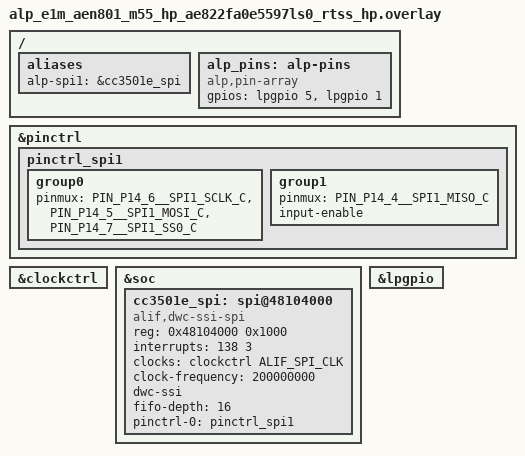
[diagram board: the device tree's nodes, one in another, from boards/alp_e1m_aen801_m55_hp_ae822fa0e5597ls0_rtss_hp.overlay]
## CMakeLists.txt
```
# SPDX-License-Identifier: Apache-2.0
cmake_minimum_required(VERSION 3.20.0)

# Auto-apply the RK055HDMIPI4MA0 DSI shield on the AEN M55-HP board targets
# this app's board.yaml actually names (`alp_e1m_aen801_m55_hp/...` and
# `alp_e1m_aen803_m55_hp/...`) -- this app's only core (board.yaml
# `cores: m55_hp:`).  The shield wires up the full Ensemble E8
# C2-MIPI-DSI DISPLAY chain (cdc200 -> mipi_dsi -> the shared D-PHY -> the
# RK055HDMIPI4MA0/HX8394 panel) on the EVK's J6 connector -- see
# examples/aen/aen-dsi-display/CMakeLists.txt for the same shield applied
# the same way (#2173).  Skipped when the caller already set SHIELD (e.g.
# `west build -DSHIELD=...`), so a user can swap in a different panel, and
# inert on every other target, including native_sim.
#
# BOARD reaches this file differently depending on the caller:
#  - a plain (non-sysbuild) `west build -b <board>` / twister's `-p
#    <platform>` both pass it in as a `-DBOARD=...` cache entry on the
#    command line, which CMake sees before this file runs, so it is
#    already a normal CMake variable below.
#  - a caller that exports BOARD instead of passing -D is covered by the
#    $ENV{BOARD} fallback.
#  - under `--sysbuild`, which is the AEN flow's documented default (see
#    docs/_aen-runbook-section.md and scripts/bench/aen/README.md),
#    sysbuild's `share/sysbuild/cmake/modules/sysbuild_extensions.cmake`
#    does NOT forward BOARD as a `-D` cache entry to the image build at
#    all (its shared_cmake_variables_list omits it); Zephyr's own
#    cmake/modules/boards.cmake resolves BOARD from the sysbuild cache
#    target instead, via zephyr_get(), *inside* find_package(Zephyr) --
#    too late to affect the regex below, which must run before
#    find_package() for SHIELD to take effect. So for sysbuild, read
#    BOARD out of the sysbuild cache file ourselves: SYSBUILD_CACHE is
#    passed to every image sub-build as a plain `-D` cache entry
#    (sysbuild_extensions.cmake's ExternalProject_Add CMAKE_ARGS), and
#    the file it points at always carries a `BOARD:STRING=<board>/<board
#    qualifiers>` line (sysbuild_extensions.cmake's sysbuild_cache()).
if(NOT DEFINED BOARD AND DEFINED ENV{BOARD})
    set(BOARD $ENV{BOARD})
endif()
if(NOT DEFINED BOARD AND DEFINED SYSBUILD_CACHE AND EXISTS "${SYSBUILD_CACHE}")
    file(STRINGS "${SYSBUILD_CACHE}" _alp_sysbuild_board_line REGEX "^BOARD:STRING=")
    if(_alp_sysbuild_board_line)
        string(REGEX REPLACE "^BOARD:STRING=" "" BOARD "${_alp_sysbuild_board_line}")
    endif()
endif()
if(DEFINED BOARD AND BOARD MATCHES "^alp_e1m_aen80[13]_m55_hp(/|$)" AND NOT DEFINED SHIELD)
    list(APPEND SHIELD e1m_evk_rk055hdmipi4ma0)
endif()

find_package(Zephyr REQUIRED HINTS $ENV{ZEPHYR_BASE})
project(iot_dashboard LANGUAGES C)

target_sources(app PRIVATE
    src/main.c
    src/dashboard_ui.c
    # Reusable SoM bring-up helper (cc3501e_bridge_bringup): the one-call
    # CC3501E bridge init this app uses so alp_wifi_open() can bind to a
    # ready bridge on E1M-AEN801 (#2112). Copyable template, same file as
    # examples/aen/aen-cc3501e-* -- see src/cc3501e_bridge.h.
    src/cc3501e_bridge.c
)
```

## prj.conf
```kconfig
# SPDX-License-Identifier: Apache-2.0
CONFIG_MAIN_STACK_SIZE=16384
CONFIG_HEAP_MEM_POOL_SIZE=262144

CONFIG_LV_Z_VDB_SIZE=50
CONFIG_LV_COLOR_DEPTH_16=y
CONFIG_LV_DEF_REFR_PERIOD=33
# LVGL doesn't ship the larger Montserrat sizes by default; the
# dashboard's big-number tiles use the 28-pt face.
CONFIG_LV_FONT_MONTSERRAT_28=y
# LVGL's own internal allocator pool -- see
# examples/display/lvgl-widgets-demo/prj.conf for why the 2048-byte
# Kconfig default is unsafe.
CONFIG_LV_Z_MEM_POOL_SIZE=131072

CONFIG_LOG=y
CONFIG_LOG_PRINTK=y

# Networking + MQTT + TLS knobs.  Real WiFi credentials come in
# via a build-time KConfig override or a CMake -D flag; the demo
# stubs out the connect step on native_sim.
CONFIG_NETWORKING=y
CONFIG_NET_IPV4=y
CONFIG_NET_TCP=y
CONFIG_NET_SOCKETS=y
CONFIG_MQTT_LIB=y
# MQTT over TLS.  This used to be forced off around the mbedtls
# ssl_misc.h break; that is fixed at its root (#2173), so the demo
# builds its real transport everywhere.
CONFIG_MQTT_LIB_TLS=y
CONFIG_DNS_RESOLVER=y

# Display subsystem.  The actual panel driver is board-specific: on AEN
# real silicon the e1m_evk_rk055hdmipi4ma0 shield (applied in
# CMakeLists.txt, #2173) brings up the RK055HDMIPI4MA0/HX8394 DSI panel
# and its `zephyr,display` chosen node, while native_sim has no panel and
# pulls CONFIG_DUMMY_DISPLAY=y from the per-example native_sim.conf
# overlay (wired in testcase.yaml).
CONFIG_DISPLAY=y

# This app binds LVGL to the panel itself via <alp/gui.h>'s
# alp_gui_lvgl_attach() (src/main.c) -- see
# examples/display/lvgl-widgets-demo/prj.conf for the full rationale
# on turning Zephyr's own lvgl auto-init off.
CONFIG_LV_Z_AUTO_INIT=n
```

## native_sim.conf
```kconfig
# SPDX-License-Identifier: Apache-2.0
#
# Native-sim Kconfig overlay for iot-dashboard.
#
# Loaded LAST via twister's `extra_args: EXTRA_CONF_FILE=...`
# (see ../testcase.yaml), so the settings here win over the
# alp.conf-emitted CONFIG_MBEDTLS=y that `libraries: [mbedtls]`
# pulls into every iot-dashboard build.
#
# The mbedtls-off block that used to live here is gone: it worked
# around the ssl_misc.h break, which is fixed at its root (#2173),
# so this target now builds the same TLS-enabled configuration the
# SoM does.  What remains is the panel wiring, which is genuinely
# native_sim-only.

# native_sim has no real DSI panel, so bind Zephyr's dummy display
# driver: it lets the dashboard link without an SDL/X11 dependency.
# On real silicon this file is NOT applied -- the RK055HDMIPI4MA0/HX8394
# panel is brought up by the e1m_evk_rk055hdmipi4ma0 shield instead
# (CMakeLists.txt, #2173) -- so the dummy-panel knob never reaches the
# real-silicon build.
CONFIG_DUMMY_DISPLAY=y

# native_sim's DTS also carries a zephyr,sdl-dc node, so CONFIG_DISPLAY=y
# (prj.conf) drags in the SDL display driver by default alongside the
# dummy one above -- see examples/display/lvgl-widgets-demo/native_sim.conf
# for why that segfaults headless. This app never opens that device,
# so keep SDL out of the build entirely.
CONFIG_SDL_DISPLAY=n

# native_sim's only entropy driver is FAKE_ENTROPY_NATIVE_SIM, whose own
# Kconfig help says it "does not generate real entropy". mbedTLS' PSA crypto
# core is on here (ALP_SDK_MBEDTLS_PSA_CRYPTO, #2173), so the weak-RNG
# refusal in zephyr/CMakeLists.txt applies and a simulator run has to
# acknowledge it (#2192). This file is native_sim-only and is NOT applied to
# a real-silicon build, so a scaffolded copy built for a SoM does not carry
# this opt-in: on AEN the SE TRNG is the default entropy source (#2192).
CONFIG_ALP_SDK_ALLOW_TEST_ENTROPY=y
```

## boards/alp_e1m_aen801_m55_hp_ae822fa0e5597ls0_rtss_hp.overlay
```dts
/*
 * Copyright (c) 2026 Alp Lab AB
 * SPDX-License-Identifier: Apache-2.0
 *
 * E1M-AEN801 M55-HP overlay for iot-dashboard.  Review on #2242 (#2173)
 * found this example shipped no AEN board overlay at all: on the AEN
 * targets the SPI1/CC3501E-bridge pads have no DT node or pinmux, so
 * cc3501e_bridge_bringup() (src/cc3501e_bridge.c, bus_id
 * CC3501E_BRIDGE_SPI_BUS_ID = 1, alp_pins WIFI_EN/NRST) could not reach
 * the CC3501E on either AEN target -- the DSI shield alone is not enough.
 *
 * This is the CC3501E bridge subset of
 * examples/peripheral-io/alp-console's bench-validated overlay -- the
 * SoM-internal Alif<->CC3501E SPI1 link + the two host-driven control
 * nets, from metadata/e1m_modules/aen/inter-chip.tsv:
 *   SPI1.SCK P14_6  MOSI P14_5  MISO P14_4   WIFI_EN P15_5  NRST P15_1_FLEX
 * iot-dashboard has no I2C sensor-manifest bus of its own here (BME280
 * comes from the board's EVK_I2C_BUS_SENSORS via board.yaml), so unlike
 * alp-console this overlay carries ONLY the bridge wiring -- no I2C2 /
 * alp-i2c0, no RGB-LED PWM.
 *
 * These are M55-HP twins of the M55-HE bridge wiring in alp-console and
 * aen-cc3501e-bringup -- no other example ships an HP bridge overlay yet.
 * SPI1 @0x48104000 and lpgpio @0x42002000 come from the shared
 * zephyr/dts/alif/ensemble_e8_peripherals.dtsi the HP board dts also
 * includes, so the addresses are the same silicon the M55-HE overlays
 * already use. Pads verified disjoint from the e1m_evk_rk055hdmipi4ma0
 * shield this app auto-applies (../CMakeLists.txt): the shield muxes only
 * P3_7 / P7_2 (I2C1, touch) plus its own I2C2 GPIO expander nets, not
 * P14_4..7 / P15_1 / P15_5.
 *
 * IRQ 138 and the whole HP bridge path are NOT bench-proven -- carried
 * over unverified from the M55-HE overlays; see their BENCH-TBD comment.
 */
#include <zephyr/dt-bindings/pinctrl/alif-ensemble-pinctrl.h>
#include <zephyr/dt-bindings/gpio/gpio.h>

&pinctrl {
	/* SPI1 master (CC3501E bridge): SCK P14_6 / MOSI P14_5 / MISO P14_4 (alt-2, _C). */
	pinctrl_spi1: pinctrl_spi1 {
		group0 {
			/* SS0 (P14_7) is now peripheral-driven -- the dwc-ssi hardware chip-select,
			 * NOT the old GPIO bodge.  Push-pull output pad like SCLK/MOSI (no input-enable);
			 * the master asserts/deasserts SS0 per transfer (write_ser). */
			pinmux = <PIN_P14_6__SPI1_SCLK_C>, <PIN_P14_5__SPI1_MOSI_C>,
				 <PIN_P14_7__SPI1_SS0_C>;
		};
		group1 {
			pinmux = <PIN_P14_4__SPI1_MISO_C>;
			input-enable;
		};
	};
};

/* P14_7 (CS) is now muxed as SPI1_SS0_C in pinctrl_spi1 -- the dwc-ssi peripheral drives
 * it in hardware per transfer.  The old gpio14 GPIO-bodge controller node is removed: a
 * GPIO claim of P14_7 would fight the SS0 pinctrl mux. */

&clockctrl {
	status = "okay";
};

&soc {
	/* DWC_ssi SPI1 -- the on-SoM CC3501E inter-chip link (NOT the edge SPI0).
	 * 4-wire: SCLK/MOSI/MISO + the hardware SS0 chip-select (P14_7 = SPI1_SS0_C,
	 * declared in pinctrl_spi1 above); clock-frequency = 200 MHz, the real SSI
	 * functional clock (E8 HWRM), so spi_dw_alif skips the failing
	 * clock-control path. */
	cc3501e_spi: spi@48104000 {
		compatible = "alif,dwc-ssi-spi";
		#address-cells = <1>;
		#size-cells = <0>;
		reg = <0x48104000 0x1000>;
		interrupts = <138 3>;          /* BENCH-TBD: SPI1 IRQ */
		clocks = <&clockctrl ALIF_SPI_CLK>;
		/* Real SSI functional clock (E8 HWRM).  Was mis-set to 400000000 here,
		 * which is not a cosmetic error: spi_dw derives BAUDR =
		 * clock-frequency / freq_hz, so a doubled input clock doubles the
		 * divider and HALVES the real SCLK -- this node was running at
		 * 500 kHz while asking for 1 MHz.  Proven via BAUDR scaling and
		 * already corrected in the aen-cc3501e-* overlays. */
		clock-frequency = <200000000>;
		dwc-ssi;
		fifo-depth = <16>;
		/* `rx-delay` IS a real devicetree property
		 * (zephyr/dts/bindings/spi/alif,dwc-ssi-spi.yaml, int, default 0) --
		 * deliberately left UNSET here, not omitted because it doesn't exist.
		 * spi_dw_alif.c writes RX_SAMPLE_DLY (reg 0xF0, ssi_clk cycles at
		 * 200 MHz = 5 ns/cycle) from this property at BOTH init and PM resume
		 * (write_rxdly(dev, info->rx_delay)); spi_dw_configure() never touches
		 * the register outside those two paths. src/cc3501e_bridge.c pokes
		 * RX_SAMPLE_DLY itself once inside cc3501e_bridge_bringup(), after
		 * this node's init already ran, so the unset (0) property here does
		 * not matter today. The overwrite is LATENT, not live: only the
		 * `#if defined CONFIG_PM_DEVICE` resume path (spi_dw_alif.c) would
		 * re-write RX_SAMPLE_DLY from this property, and nothing in this app
		 * enables CONFIG_PM_DEVICE. CC3501E_BRIDGE_RX_SAMPLE_DLY is 4,
		 * silicon-tuned for ~25 MHz on E1M-AEN803 serial 2026W36-0002 --
		 * NOT 6 / ~14.3 MHz, an earlier measurement the header itself
		 * documents as stale and not comparable (see cc3501e_bridge.h's own
		 * correction). */
		pinctrl-0 = <&pinctrl_spi1>;
		pinctrl-names = "default";
		status = "okay";
	};
};

/* LP GPIO island: WIFI_EN (P15_5) + E_WIFI.NRST (P15_1_FLEX) as outputs. */
&lpgpio {
	status = "okay";
};

/ {
	aliases {
		alp-spi1 = &cc3501e_spi;   /* bus_id 1 in cc3501e_bridge_bringup() */
	};

	/* SoM-internal CC3501E control nets, in CC3501E_PIN_* index order. */
	alp_pins: alp-pins {
		compatible = "alp,pin-array";
		gpios = <&lpgpio 5 GPIO_ACTIVE_HIGH>,   /* [0] WIFI_EN     (P15_5)      */
			<&lpgpio 1 GPIO_ACTIVE_HIGH>;   /* [1] E_WIFI.NRST (P15_1_FLEX) */
	};
};
```

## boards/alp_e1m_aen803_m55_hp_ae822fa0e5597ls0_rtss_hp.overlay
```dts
/*
 * Copyright (c) 2026 Alp Lab AB
 * SPDX-License-Identifier: Apache-2.0
 *
 * E1M-AEN803 M55-HP overlay for iot-dashboard.  Review on #2242 (#2173)
 * found this example shipped no AEN board overlay at all: on the AEN
 * targets the SPI1/CC3501E-bridge pads have no DT node or pinmux, so
 * cc3501e_bridge_bringup() (src/cc3501e_bridge.c, bus_id
 * CC3501E_BRIDGE_SPI_BUS_ID = 1, alp_pins WIFI_EN/NRST) could not reach
 * the CC3501E on either AEN target -- the DSI shield alone is not enough.
 *
 * This is the CC3501E bridge subset of
 * examples/peripheral-io/alp-console's bench-validated overlay -- the
 * SoM-internal Alif<->CC3501E SPI1 link + the two host-driven control
 * nets, from metadata/e1m_modules/aen/inter-chip.tsv:
 *   SPI1.SCK P14_6  MOSI P14_5  MISO P14_4   WIFI_EN P15_5  NRST P15_1_FLEX
 * iot-dashboard has no I2C sensor-manifest bus of its own here (BME280
 * comes from the board's EVK_I2C_BUS_SENSORS via board.yaml), so unlike
 * alp-console this overlay carries ONLY the bridge wiring -- no I2C2 /
 * alp-i2c0, no RGB-LED PWM.
 *
 * These are M55-HP twins of the M55-HE bridge wiring in alp-console and
 * aen-cc3501e-bringup -- no other example ships an HP bridge overlay yet.
 * SPI1 @0x48104000 and lpgpio @0x42002000 come from the shared
 * zephyr/dts/alif/ensemble_e8_peripherals.dtsi the HP board dts also
 * includes, so the addresses are the same silicon the M55-HE overlays
 * already use. Pads verified disjoint from the e1m_evk_rk055hdmipi4ma0
 * shield this app auto-applies (../CMakeLists.txt): the shield muxes only
 * P3_7 / P7_2 (I2C1, touch) plus its own I2C2 GPIO expander nets, not
 * P14_4..7 / P15_1 / P15_5.
 *
 * IRQ 138 and the whole HP bridge path are NOT bench-proven -- carried
 * over unverified from the M55-HE overlays; see their BENCH-TBD comment.
 */
#include <zephyr/dt-bindings/pinctrl/alif-ensemble-pinctrl.h>
#include <zephyr/dt-bindings/gpio/gpio.h>

&pinctrl {
	/* SPI1 master (CC3501E bridge): SCK P14_6 / MOSI P14_5 / MISO P14_4 (alt-2, _C). */
	pinctrl_spi1: pinctrl_spi1 {
		group0 {
			/* SS0 (P14_7) is now peripheral-driven -- the dwc-ssi hardware chip-select,
			 * NOT the old GPIO bodge.  Push-pull output pad like SCLK/MOSI (no input-enable);
			 * the master asserts/deasserts SS0 per transfer (write_ser). */
			pinmux = <PIN_P14_6__SPI1_SCLK_C>, <PIN_P14_5__SPI1_MOSI_C>,
				 <PIN_P14_7__SPI1_SS0_C>;
		};
		group1 {
			pinmux = <PIN_P14_4__SPI1_MISO_C>;
			input-enable;
		};
	};
};

/* P14_7 (CS) is now muxed as SPI1_SS0_C in pinctrl_spi1 -- the dwc-ssi peripheral drives
 * it in hardware per transfer.  The old gpio14 GPIO-bodge controller node is removed: a
 * GPIO claim of P14_7 would fight the SS0 pinctrl mux. */

&clockctrl {
	status = "okay";
};

&soc {
	/* DWC_ssi SPI1 -- the on-SoM CC3501E inter-chip link (NOT the edge SPI0).
	 * 4-wire: SCLK/MOSI/MISO + the hardware SS0 chip-select (P14_7 = SPI1_SS0_C,
	 * declared in pinctrl_spi1 above); clock-frequency = 200 MHz, the real SSI
	 * functional clock (E8 HWRM), so spi_dw_alif skips the failing
	 * clock-control path. */
	cc3501e_spi: spi@48104000 {
		compatible = "alif,dwc-ssi-spi";
		#address-cells = <1>;
		#size-cells = <0>;
		reg = <0x48104000 0x1000>;
		interrupts = <138 3>;          /* BENCH-TBD: SPI1 IRQ */
		clocks = <&clockctrl ALIF_SPI_CLK>;
		/* Real SSI functional clock (E8 HWRM).  Was mis-set to 400000000 here,
		 * which is not a cosmetic error: spi_dw derives BAUDR =
		 * clock-frequency / freq_hz, so a doubled input clock doubles the
		 * divider and HALVES the real SCLK -- this node was running at
		 * 500 kHz while asking for 1 MHz.  Proven via BAUDR scaling and
		 * already corrected in the aen-cc3501e-* overlays. */
		clock-frequency = <200000000>;
		dwc-ssi;
		fifo-depth = <16>;
		/* `rx-delay` IS a real devicetree property
		 * (zephyr/dts/bindings/spi/alif,dwc-ssi-spi.yaml, int, default 0) --
		 * deliberately left UNSET here, not omitted because it doesn't exist.
		 * spi_dw_alif.c writes RX_SAMPLE_DLY (reg 0xF0, ssi_clk cycles at
		 * 200 MHz = 5 ns/cycle) from this property at BOTH init and PM resume
		 * (write_rxdly(dev, info->rx_delay)); spi_dw_configure() never touches
		 * the register outside those two paths. src/cc3501e_bridge.c pokes
		 * RX_SAMPLE_DLY itself once inside cc3501e_bridge_bringup(), after
		 * this node's init already ran, so the unset (0) property here does
		 * not matter today. The overwrite is LATENT, not live: only the
		 * `#if defined CONFIG_PM_DEVICE` resume path (spi_dw_alif.c) would
		 * re-write RX_SAMPLE_DLY from this property, and nothing in this app
		 * enables CONFIG_PM_DEVICE. CC3501E_BRIDGE_RX_SAMPLE_DLY is 4,
		 * silicon-tuned for ~25 MHz on E1M-AEN803 serial 2026W36-0002 --
		 * NOT 6 / ~14.3 MHz, an earlier measurement the header itself
		 * documents as stale and not comparable (see cc3501e_bridge.h's own
		 * correction). */
		pinctrl-0 = <&pinctrl_spi1>;
		pinctrl-names = "default";
		status = "okay";
	};
};

/* LP GPIO island: WIFI_EN (P15_5) + E_WIFI.NRST (P15_1_FLEX) as outputs. */
&lpgpio {
	status = "okay";
};

/ {
	aliases {
		alp-spi1 = &cc3501e_spi;   /* bus_id 1 in cc3501e_bridge_bringup() */
	};

	/* SoM-internal CC3501E control nets, in CC3501E_PIN_* index order. */
	alp_pins: alp-pins {
		compatible = "alp,pin-array";
		gpios = <&lpgpio 5 GPIO_ACTIVE_HIGH>,   /* [0] WIFI_EN     (P15_5)      */
			<&lpgpio 1 GPIO_ACTIVE_HIGH>;   /* [1] E_WIFI.NRST (P15_1_FLEX) */
	};
};
```

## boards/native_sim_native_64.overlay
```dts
/*
 * Copyright 2026 Alp Lab AB
 * SPDX-License-Identifier: Apache-2.0
 *
 * native_sim board overlay -- chooses zephyr's dummy display
 * driver so the LVGL demo links without a real display chip.
 * Real-silicon builds (alif / v2n) bring up the actual panel: on AEN
 * that's the RK055HDMIPI4MA0 DSI panel via the e1m_evk_rk055hdmipi4ma0
 * shield (CMakeLists.txt, #2173); other SoMs bring up their own panel
 * (e.g. ILI9488) via the SoM board overlay.
 *
 * Two references to the same dummy_dc node -- see
 * examples/display/lvgl-widgets-demo/boards/native_sim_native_64.overlay
 * for why `chosen { zephyr,display }` and `aliases { alp-display0 }`
 * both point at it (one satisfies the lvgl module's compile-time
 * requirement, the other is what src/main.c actually opens).
 */

/ {
	chosen {
		zephyr,display = &dummy_dc;
	};

	aliases {
		alp-display0 = &dummy_dc;
	};

	dummy_dc: dummy_dc {
		compatible = "zephyr,dummy-dc";
		height = <320>;
		width = <240>;
	};
};
```

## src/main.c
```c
/*
 * Copyright 2026 Alp Lab AB
 * SPDX-License-Identifier: Apache-2.0
 *
 * iot-dashboard
 * =============
 *
 * Customer-facing IoT demo: an E1M-AEN module reads BME280
 * environment samples (temperature, humidity, pressure), publishes
 * them to an MQTT broker over TLS, and renders the live values +
 * connection state on a 240×320 LVGL dashboard.
 *
 *
 * ── End-to-end SDK demo ────────────────────────────────────────
 *
 *   ┌──────────────────┐  I²C0   ┌─────────┐
 *   │  E1M-AEN801 SoM  │ ──────▶ │ BME280  │ (T / H / P)
 *   │ + Cortex-M55 HP  │         └─────────┘
 *   └────────┬─────────┘
 *            │ bridge ┌─────────────────────────┐
 *            ├──────▶ │ TI CC3501E Wi-Fi/BLE    │ ── TLS ─▶ broker.example
 *            │        └─────────────────────────┘
 *            │  I²C0  ┌─────────────────────────┐
 *            ├──────▶ │ OPTIGA Trust M          │  planned trust anchor
 *            │        └─────────────────────────┘
 *            │ shield ┌─────────────────────────┐
 *            └──────▶ │ RK055HDMIPI4MA0 DSI     │ ── LVGL dashboard
 *                     │ panel (HX8394, EVK J6)  │
 *                     └─────────────────────────┘
 *
 *
 * ── What "verified" would mean ─────────────────────────────────
 *
 * Today the path is paper-correct; HiL flips it to verified when:
 *   1. WiFi associates with a real AP.
 *   2. TLS handshake offload through OPTIGA is wired and completes in < 1 s.
 *   3. The dashboard refreshes within 250 ms of a BME280 sample.
 *   4. The publish/connect cycle survives a 24h soak.
 * That's the v0.6 AEN HiL story.
 *
 * native_sim builds end-to-end but stubs WiFi/TLS -- runs the
 * UI logic against simulated sensor values.
 */

#include <zephyr/kernel.h>
#include <zephyr/logging/log.h>
#include <stdio.h>

#include "alp/peripheral.h"
#include "alp/iot.h"
#include "alp/chips/bme280.h"
#include "cc3501e_bridge.h" /* cc3501e_bridge_bringup() -- the SoM bring-up template, #2112 */
#include <alp/display.h>
#include <alp/gui.h>

#include <lvgl.h>

/* EVK_I2C_BUS_SENSORS is a board-macro from the generated routes header
 * (= ALP_E1M_I2C0); rebind it in board.yaml `pins:` to port to another board. */
#include "alp/boards/alp_e1m_evk_routes.h"

#include "dashboard_ui.h"

/* On E1M-AEN801 with the CC3501E bridge attached, alp_wifi_connect() routes
 * to the CC3501E backend (src/backends/wifi/cc3501e.c), and the bridge's own
 * worst case for one STA connect is 10s Wlan_RoleUp + 30s L2 association +
 * a 30s DHCP-lease poll (hal/ti/cc3501e_hw_ti_wifi.c) = 70s. This same source
 * also builds against a V2N board.yaml (Linux-owned Murata/CYW Wi-Fi); on
 * that backend this value is only an upper bound, not a derived worst
 * case. */
#define WIFI_CONNECT_TIMEOUT_MS 75000u

LOG_MODULE_REGISTER(iot_dashboard, LOG_LEVEL_INF);

static bme280_t    s_env;
static alp_i2c_t  *s_i2c;
static alp_mqtt_t *s_mqtt;

/* The shared dashboard snapshot.  Single-writer (sensor thread)
 * single-reader (main UI thread); volatile-snapshot read in
 * main() is correct without locks. */
static dashboard_state_t g_state;

K_THREAD_STACK_DEFINE(sensor_stack, 4096);
static struct k_thread sensor_thread;

static void sensor_entry(void *p1, void *p2, void *p3)
{
	ARG_UNUSED(p1);
	ARG_UNUSED(p2);
	ARG_UNUSED(p3);
	/* Sample at 1 Hz -- BME280 is slow + customers want a
     * comfortable refresh rate on the dashboard. */
	while (1) {
		bme280_raw_t raw = { 0 };
		if (bme280_read_raw(&s_env, &raw) == ALP_OK) {
			bme280_compensated_t cc = { 0 };
			bme280_compensate(&s_env, &raw, &cc);
			g_state.temp_c         = cc.temperature_c100 / 100.f;
			g_state.humid_pct      = cc.humidity_milli_pct / 1024.f;
			g_state.pressure_hpa   = cc.pressure_pa / 100.f;
			g_state.last_update_ms = k_uptime_get_32();

			/* Push the same sample to MQTT if connected. */
			if (s_mqtt != NULL) {
				char payload[96];
				int  n = snprintf(payload,
				                  sizeof(payload),
				                  "{\"t\":%.2f,\"h\":%.1f,\"p\":%.1f}",
				                  (double)g_state.temp_c,
				                  (double)g_state.humid_pct,
				                  (double)g_state.pressure_hpa);
				if (n > 0) {
					(void)alp_mqtt_publish(s_mqtt,
					                       "alp/env",
					                       (const uint8_t *)payload,
					                       (size_t)n,
					                       ALP_MQTT_QOS_0,
					                       /*retain=*/false);
				}
			}
		}
		k_msleep(1000);
	}
}

int main(void)
{
	LOG_INF("iot-dashboard demo starting");

	/* Sensor bus + chip bring-up. */
	s_i2c = alp_i2c_open(&(alp_i2c_config_t){
	    .bus_id     = EVK_I2C_BUS_SENSORS, /* = ALP_E1M_I2C0 */
	    .bitrate_hz = 400000,
	});
	if (s_i2c == NULL || bme280_init(&s_env, s_i2c, BME280_I2C_ADDR_LOW) != ALP_OK) {
		LOG_WRN("BME280 unavailable; dashboard will show zero readings");
	} else {
		bme280_set_sampling(&s_env,
		                    BME280_OVERSAMPLING_X1,
		                    BME280_OVERSAMPLING_X1,
		                    BME280_OVERSAMPLING_X1,
		                    BME280_MODE_NORMAL,
		                    BME280_STANDBY_125_MS,
		                    BME280_FILTER_OFF);
	}

	/* WiFi + MQTT connect.  On native_sim this drops to the
     * <alp/iot.h> NOSUPPORT stub -- the UI still runs against
     * the in-memory dashboard_state_t.
     *
     * On E1M-AEN801, alp_wifi_open() only resolves to the CC3501E backend
     * once a live bridge is attached (#2112) -- bring it up first, the
     * same copyable template every examples/aen/aen-cc3501e-* app uses.
     * On native_sim this fails fast (ALP_ERR_NOT_PRESENT_ON_THIS_SOC --
     * no SPI/GPIO backend matches that SoC ref) and alp_wifi_open() below
     * still returns NULL, unchanged from before. */
	static cc3501e_t s_bridge  = { 0 };
	alp_status_t     bridge_rc = cc3501e_bridge_bringup(&s_bridge);
	LOG_INF("cc3501e_bridge_bringup -> %d", (int)bridge_rc);

	alp_wifi_t *wifi = alp_wifi_open();
	if (wifi) {
		(void)alp_wifi_connect(wifi,
		                       &(alp_wifi_credentials_t){
		                           .ssid = "alp-demo-ssid",
		                           .psk  = "demo-password",
		                       },
		                       /*timeout_ms=*/WIFI_CONNECT_TIMEOUT_MS);
	}
	static const alp_mqtt_tls_config_t s_tls = { 0 }; /* defaults: OS CA, verify peer. */
	s_mqtt                                   = alp_mqtt_open(&(alp_mqtt_config_t){
	    .broker_uri = "mqtts://broker.example.com:8883",
	    .client_id  = "alp-iot-dashboard-demo",
	    .tls        = &s_tls,
	});
	if (s_mqtt == NULL) {
		LOG_WRN("MQTT broker unreachable; running standalone");
	}

	/* Display + LVGL bring-up.  Open the panel through the portable
     * <alp/display.h> surface, then bind LVGL to it via <alp/gui.h>
     * -- see examples/display/lvgl-widgets-demo/src/main.c for the
     * full rationale on this open -> lv_init -> tick -> attach
     * sequence, and why CONFIG_LV_Z_AUTO_INIT=n (prj.conf) is
     * required alongside it. */
	alp_display_config_t display_cfg = ALP_DISPLAY_CONFIG_DEFAULT(0);
	/* This app owns the panel, so it opts in to driving the mode.
	 * Ignored on Zephyr; on Yocto/Linux it is required, because
	 * opening a display there reprograms a live output (#1143). */
	display_cfg.allow_modeset        = true;
	alp_display_t       *display     = alp_display_open(&display_cfg);
	if (display == NULL) {
		LOG_ERR("display open failed (err=%d)", (int)alp_last_error());
		return 1;
	}
	lv_init();
	lv_tick_set_cb(k_uptime_get_32);

	alp_status_t attach_status = alp_gui_lvgl_attach(display);
	if (attach_status != ALP_OK) {
		LOG_ERR("alp_gui_lvgl_attach failed (err=%d)", (int)attach_status);
		return 1;
	}

	dashboard_ui_build();

	/* Spawn the sensor thread. */
	k_thread_create(&sensor_thread,
	                sensor_stack,
	                K_THREAD_STACK_SIZEOF(sensor_stack),
	                sensor_entry,
	                NULL,
	                NULL,
	                NULL,
	                K_PRIO_PREEMPT(4),
	                0,
	                K_NO_WAIT);
	k_thread_name_set(&sensor_thread, "env_sensor");

	/* Render loop. */
	while (1) {
		dashboard_state_t snap = g_state;
		snap.mqtt_connected    = (s_mqtt != NULL);
		dashboard_ui_apply(&snap);

		const uint32_t sleep_ms = lv_timer_handler();
		k_msleep(MIN(sleep_ms, 10u));
	}

	return 0;
}
```

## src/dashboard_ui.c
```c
/*
 * Copyright 2026 Alp Lab AB
 * SPDX-License-Identifier: Apache-2.0
 *
 * Dashboard layout for iot-dashboard -- the LVGL view layer.
 *
 * This file owns the on-screen widgets and nothing else: it knows how to
 * BUILD the dashboard once and how to RE-PAINT it from a plain data struct.
 * It deliberately has no knowledge of I2C, the BME280, MQTT, or threads --
 * main.c samples the sensor and hands this layer a finished snapshot. Keeping
 * the view free of device code is what lets the same UI run unchanged on the
 * ST7789 panel and on native_sim's framebuffer emulator.
 *
 * The split is the LVGL idiom and the reason for the two entry points:
 *   - dashboard_ui_build() runs ONCE at startup. It creates the widget tree
 *     and stashes each widget handle in a file-static pointer.
 *   - dashboard_ui_apply() runs EVERY frame. It only mutates the text/values
 *     of those cached handles -- no allocation, no re-layout -- so the render
 *     loop stays cheap.
 *
 * Three tiles + a status strip, each a fixed accent colour (no per-value
 * recolouring -- the colour is set once in build()):
 *   - Temperature  large 28px numeric, warm orange.
 *   - Humidity     large 28px numeric, blue.
 *   - Pressure     white numeric plus a green sparkline of recent samples.
 *   - Status strip grey, shows MQTT connection state + last-update timestamp.
 *
 * main.c's sensor thread refreshes the shared state at 1 Hz; the render loop
 * calls dashboard_ui_apply() far more often, so most frames just re-draw the
 * last sample. That is fine -- the UI is a viewer, the sensor sets the pace.
 */

#include <stdio.h>

#include <lvgl.h>

#include "dashboard_ui.h"

/* Widget handles cached at build() time so apply() can update them in place
 * every frame. They stay file-static because LVGL owns the objects (they live
 * on the active screen); we only borrow the pointers to push new values. */
static lv_obj_t          *s_lbl_temp;
static lv_obj_t          *s_lbl_humid;
static lv_obj_t          *s_lbl_pressure;
static lv_obj_t          *s_lbl_status;
static lv_obj_t          *s_chart;
static lv_chart_series_t *s_pressure_series;

void dashboard_ui_build(void)
{
	/* Everything hangs off the active screen so the layout follows whatever
	 * display LVGL was initialised against. Dark near-black background so the
	 * accent-coloured readouts pop on the small panel. */
	lv_obj_t *scr = lv_screen_active();
	lv_obj_set_style_bg_color(scr, lv_color_hex(0x101820), 0);

	/* Temperature tile: top of the stack, large font, warm orange accent.
	 * Seeded with an em-dash placeholder so the first frame is sensible
	 * before any BME280 sample has arrived. */
	s_lbl_temp = lv_label_create(scr);
	lv_obj_set_pos(s_lbl_temp, 8, 8);
	lv_obj_set_style_text_color(s_lbl_temp, lv_color_hex(0xFF6040), 0);
	lv_obj_set_style_text_font(s_lbl_temp, &lv_font_montserrat_28, 0);
	lv_label_set_text(s_lbl_temp, "--.- °C");

	/* Humidity tile: same large font, blue accent to read distinctly from the
	 * temperature line directly above it. */
	s_lbl_humid = lv_label_create(scr);
	lv_obj_set_pos(s_lbl_humid, 8, 60);
	lv_obj_set_style_text_color(s_lbl_humid, lv_color_hex(0x40A0FF), 0);
	lv_obj_set_style_text_font(s_lbl_humid, &lv_font_montserrat_28, 0);
	lv_label_set_text(s_lbl_humid, "--.- %RH");

	/* Pressure: a white numeric readout with a sparkline beneath it, since the
	 * trend over time is more telling than any single barometric reading. */
	s_lbl_pressure = lv_label_create(scr);
	lv_obj_set_pos(s_lbl_pressure, 8, 112);
	lv_obj_set_style_text_color(s_lbl_pressure, lv_color_hex(0xFFFFFF), 0);
	lv_label_set_text(s_lbl_pressure, "---- hPa");

	/* 60-point chart = a rolling one-minute window at the sensor's 1 Hz
	 * cadence. The Y range is pinned to 950..1050 hPa (normal sea-level
	 * weather band) rather than auto-scaled, so small real fluctuations stay
	 * visible and noise doesn't make the line jump to fill the box. */
	s_chart = lv_chart_create(scr);
	lv_obj_set_size(s_chart, 224, 100);
	lv_obj_set_pos(s_chart, 8, 140);
	lv_chart_set_point_count(s_chart, 60);
	lv_chart_set_range(s_chart, LV_CHART_AXIS_PRIMARY_Y, 950, 1050);
	s_pressure_series =
	    lv_chart_add_series(s_chart, lv_color_hex(0x40FF80), LV_CHART_AXIS_PRIMARY_Y);

	/* Status strip pinned to the bottom: muted grey because it is chrome, not
	 * data -- it reports the MQTT link state and when the last sample landed. */
	s_lbl_status = lv_label_create(scr);
	lv_obj_set_pos(s_lbl_status, 8, 260);
	lv_obj_set_style_text_color(s_lbl_status, lv_color_hex(0x808890), 0);
	lv_label_set_text(s_lbl_status, "MQTT: --   updated --");
}

/* Re-paint the dashboard from an immutable snapshot. `s` is a by-value copy
 * main.c took of the shared state, so this function never races the sensor
 * thread and never blocks it. Widths in the format strings are fixed so the
 * numbers don't shift left/right as digits appear and disappear. */
void dashboard_ui_apply(const dashboard_state_t *s)
{
	char buf[64];

	snprintf(buf, sizeof(buf), "%5.1f °C", (double)s->temp_c);
	lv_label_set_text(s_lbl_temp, buf);

	snprintf(buf, sizeof(buf), "%5.1f %%RH", (double)s->humid_pct);
	lv_label_set_text(s_lbl_humid, buf);

	snprintf(buf, sizeof(buf), "%6.1f hPa", (double)s->pressure_hpa);
	lv_label_set_text(s_lbl_pressure, buf);

	/* Scroll one sample into the sparkline: set_next_value advances LVGL's
	 * internal ring buffer (oldest point drops off the left), then refresh
	 * redraws it. Truncating to int32 is fine -- 1 hPa resolution on a chart
	 * that spans a 100 hPa window is below one pixel. */
	lv_chart_set_next_value(s_chart, s_pressure_series, (int32_t)s->pressure_hpa);
	lv_chart_refresh(s_chart);

	snprintf(buf,
	         sizeof(buf),
	         "MQTT: %s   t=%u ms",
	         s->mqtt_connected ? "CONNECTED" : "offline",
	         (unsigned)s->last_update_ms);
	lv_label_set_text(s_lbl_status, buf);
}
```

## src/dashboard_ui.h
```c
/*
 * Copyright 2026 Alp Lab AB
 * SPDX-License-Identifier: Apache-2.0
 */

#ifndef IOT_DASHBOARD_UI_H
#define IOT_DASHBOARD_UI_H

#include <stdint.h>
#include <stdbool.h>

#ifdef __cplusplus
extern "C" {
#endif

typedef struct {
	float    temp_c;
	float    humid_pct;
	float    pressure_hpa;
	bool     mqtt_connected;
	uint32_t last_update_ms;
} dashboard_state_t;

void dashboard_ui_build(void);
void dashboard_ui_apply(const dashboard_state_t *s);

#ifdef __cplusplus
} /* extern "C" */
#endif

#endif /* IOT_DASHBOARD_UI_H */
```
